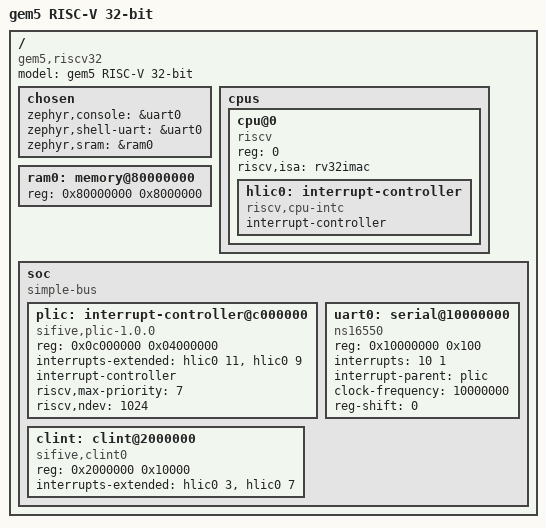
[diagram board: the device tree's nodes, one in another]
/dts-v1/;

/ {
	#address-cells = <1>;
	#size-cells = <1>;
	model = "gem5 RISC-V 32-bit";
	compatible = "gem5,riscv32";

	chosen {
		zephyr,console = &uart0;
		zephyr,shell-uart = &uart0;
		zephyr,sram = &ram0;
	};

	cpus {
		#address-cells = <1>;
		#size-cells = <0>;

		cpu@0 {
			device_type = "cpu";
			reg = <0>;
			status = "okay";
			compatible = "riscv";
			riscv,isa = "rv32imac";

			hlic0: interrupt-controller {
				compatible = "riscv,cpu-intc";
				#address-cells = <0>;
				#interrupt-cells = <1>;
				interrupt-controller;
			};
		};
	};

	ram0: memory@80000000 {
		device_type = "memory";
		reg = <0x80000000 0x8000000>; // 128MB
	};

	soc {
		#address-cells = <1>;
		#size-cells = <1>;
		compatible = "simple-bus";
		ranges;

		plic: interrupt-controller@c000000 {
			compatible = "sifive,plic-1.0.0";
			reg = <0x0c000000 0x04000000>;
			interrupts-extended = <&hlic0 11 &hlic0 9>;
			interrupt-controller;
			#address-cells = <0>;
			#interrupt-cells = <2>;
			riscv,max-priority = <7>;
			riscv,ndev = <1024>;
		};

		clint: clint@2000000 {
			compatible = "sifive,clint0";
			reg = <0x2000000 0x10000>;
			interrupts-extended = <&hlic0 3 &hlic0 7>;
		};

		uart0: serial@10000000 {
			compatible = "ns16550";
			reg = <0x10000000 0x100>;
			interrupts = <10 1>;
			interrupt-parent = <&plic>;
			clock-frequency = <10000000>;
			reg-shift = <0>;
			status = "okay";
		};
	};
};
